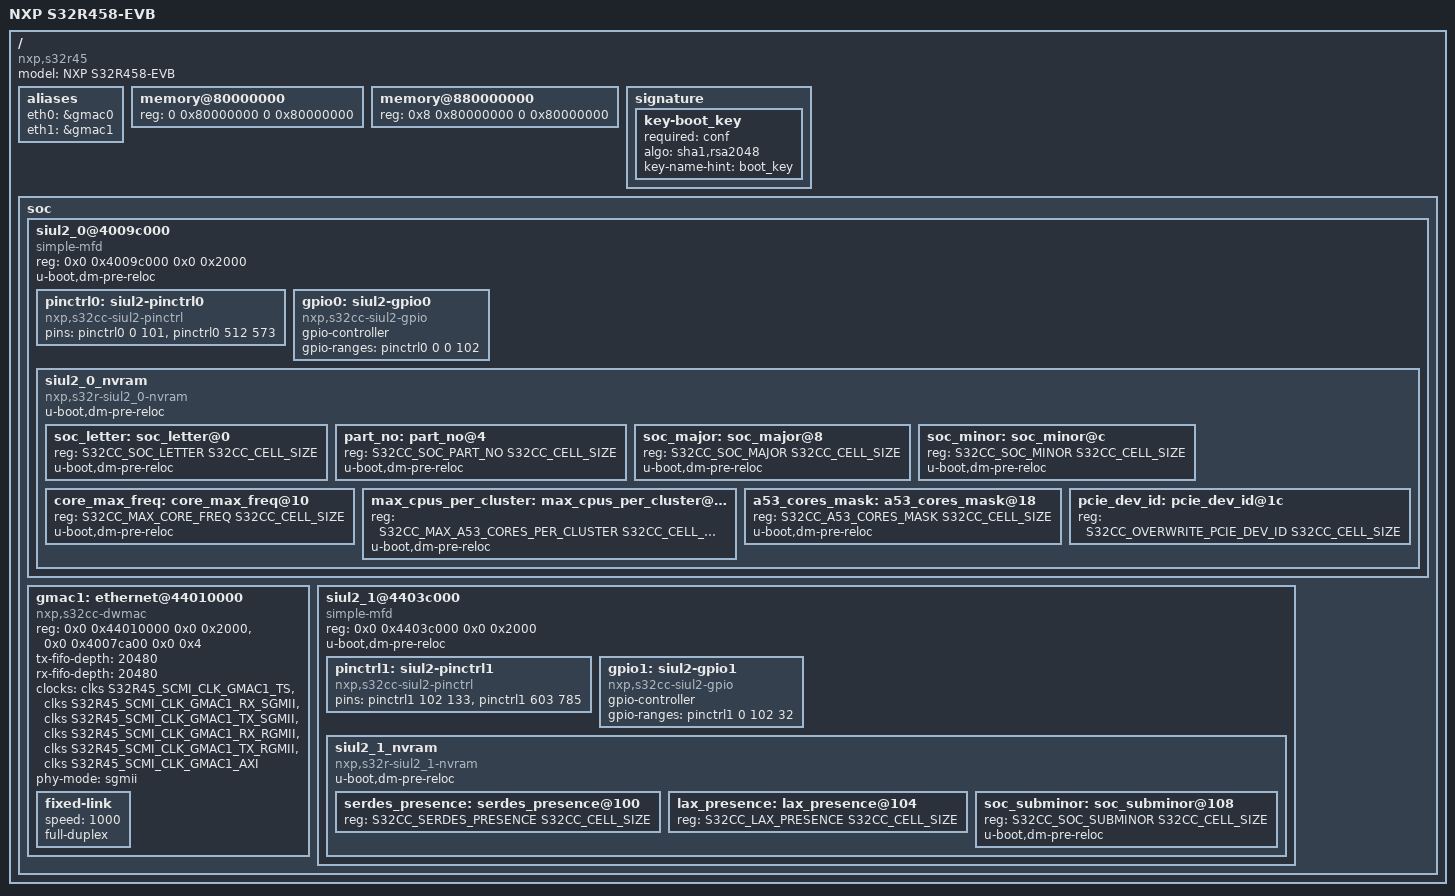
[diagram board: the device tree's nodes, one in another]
// SPDX-License-Identifier: GPL-2.0+
/*
 * Copyright 2017-2022 NXP
 *
 * This program is free software; you can redistribute it and/or modify
 * it under the terms of the GNU General Public License as published by
 * the Free Software Foundation; either version 2 of the License, or
 * (at your option) any later version.
 */
#include <dt-bindings/clock/s32r45-scmi-clock.h>
#include <dt-bindings/gpio/gpio.h>
#include <dt-bindings/nvmem/s32cc-siul2-nvmem.h>
#include <dt-bindings/pinctrl/s32r45-pinctrl.h>

#include "s32cc.dtsi"
/ {
	model = "NXP S32R458-EVB";
	compatible = "nxp,s32r45";

	aliases {
		eth0 = &gmac0;
		eth1 = &gmac1;
	};

	memory@80000000 {
		device_type = "memory";
		reg = <0 0x80000000 0 0x80000000>;
	};

	memory@880000000 {
		device_type = "memory";
		reg = <0x8 0x80000000 0 0x80000000>;
	};

	signature {
		key-boot_key {
			required = "conf";
			algo = "sha1,rsa2048";
			key-name-hint = "boot_key";
		};
	};

	soc {
		siul2_0@4009c000 {
			compatible = "simple-mfd";
			status = "okay";
			reg = <0x0 0x4009c000 0x0 0x2000>;
			u-boot,dm-pre-reloc;

			pinctrl0: siul2-pinctrl0 {
				compatible = "nxp,s32cc-siul2-pinctrl";
				#pinctrl-cells = <2>;
				/* MSCR range */
				pins = <&pinctrl0 0 101>,
				/* IMCR range */
				<&pinctrl0 512 573>;
				status = "okay";
			};

			gpio0: siul2-gpio0 {
				compatible = "nxp,s32cc-siul2-gpio";
				#gpio-cells = <2>;
				gpio-controller;
				gpio-ranges = <&pinctrl0 0 0 102>;
				status = "okay";
			};

			siul2_0_nvram: siul2_0_nvram {
				#address-cells = <1>;
				#size-cells = <1>;

				compatible = "nxp,s32r-siul2_0-nvram";
				status = "okay";
				u-boot,dm-pre-reloc;

				soc_letter: soc_letter@0 {
					reg = <S32CC_SOC_LETTER S32CC_CELL_SIZE>;
					u-boot,dm-pre-reloc;
				};

				part_no: part_no@4 {
					reg = <S32CC_SOC_PART_NO S32CC_CELL_SIZE>;
					u-boot,dm-pre-reloc;
				};

				soc_major: soc_major@8 {
					reg = <S32CC_SOC_MAJOR S32CC_CELL_SIZE>;
					u-boot,dm-pre-reloc;
				};

				soc_minor: soc_minor@c {
					reg = <S32CC_SOC_MINOR S32CC_CELL_SIZE>;
					u-boot,dm-pre-reloc;
				};

				core_max_freq: core_max_freq@10 {
					reg = <S32CC_MAX_CORE_FREQ S32CC_CELL_SIZE>;
					u-boot,dm-pre-reloc;
				};

				max_cpus_per_cluster: max_cpus_per_cluster@14 {
					reg = <S32CC_MAX_A53_CORES_PER_CLUSTER
					    S32CC_CELL_SIZE>;
					u-boot,dm-pre-reloc;
				};

				a53_cores_mask: a53_cores_mask@18 {
					reg = <S32CC_A53_CORES_MASK S32CC_CELL_SIZE>;
					u-boot,dm-pre-reloc;
				};

				pcie_dev_id: pcie_dev_id@1c {
					reg = <S32CC_OVERWRITE_PCIE_DEV_ID
					    S32CC_CELL_SIZE>;
				};

			};
		};

		gmac1: ethernet@44010000 {
			compatible = "nxp,s32cc-dwmac";
			reg = <0x0 0x44010000 0x0 0x2000>, /* gmac IP */
			      <0x0 0x4007ca00 0x0 0x4>;    /* S32 CTRL_STS reg */
			tx-fifo-depth = <20480>;
			rx-fifo-depth = <20480>;
			clocks = <&clks S32R45_SCMI_CLK_GMAC1_TS>,
					<&clks S32R45_SCMI_CLK_GMAC1_RX_SGMII>,
					<&clks S32R45_SCMI_CLK_GMAC1_TX_SGMII>,
					<&clks S32R45_SCMI_CLK_GMAC1_RX_RGMII>,
					<&clks S32R45_SCMI_CLK_GMAC1_TX_RGMII>,
					<&clks S32R45_SCMI_CLK_GMAC1_AXI>;
			clock-names = "ts", "rx_sgmii", "tx_sgmii",
							"rx_rgmii", "tx_rgmii", "axi";
			status = "okay";
			phy-mode = "sgmii";
			fixed-link {
				speed = <1000>;
				full-duplex;
			};
		};

		siul2_1@4403c000 {
			compatible = "simple-mfd";
			status = "okay";
			reg = <0x0 0x4403c000 0x0 0x2000>;
			u-boot,dm-pre-reloc;

			pinctrl1: siul2-pinctrl1 {
				compatible = "nxp,s32cc-siul2-pinctrl";
				#pinctrl-cells = <2>;
				/* MSCR range */
				pins = <&pinctrl1 102 133>,
				/* IMCR range */
				<&pinctrl1 603 785>;
				status = "okay";
			};

			gpio1: siul2-gpio1 {
				compatible = "nxp,s32cc-siul2-gpio";
				gpio-controller;
				#gpio-cells = <2>;
				gpio-ranges = <&pinctrl1 0 102 32>;
				status = "okay";
			};

			siul2_1_nvram {
				#address-cells = <1>;
				#size-cells = <1>;

				compatible = "nxp,s32r-siul2_1-nvram";
				status = "okay";
				u-boot,dm-pre-reloc;

				serdes_presence: serdes_presence@100 {
					reg = <S32CC_SERDES_PRESENCE S32CC_CELL_SIZE>;
				};

				lax_presence: lax_presence@104 {
					reg = <S32CC_LAX_PRESENCE S32CC_CELL_SIZE>;
				};

				soc_subminor: soc_subminor@108 {
					reg = <S32CC_SOC_SUBMINOR S32CC_CELL_SIZE>;
					u-boot,dm-pre-reloc;
				};

			};
		};
	};
};
